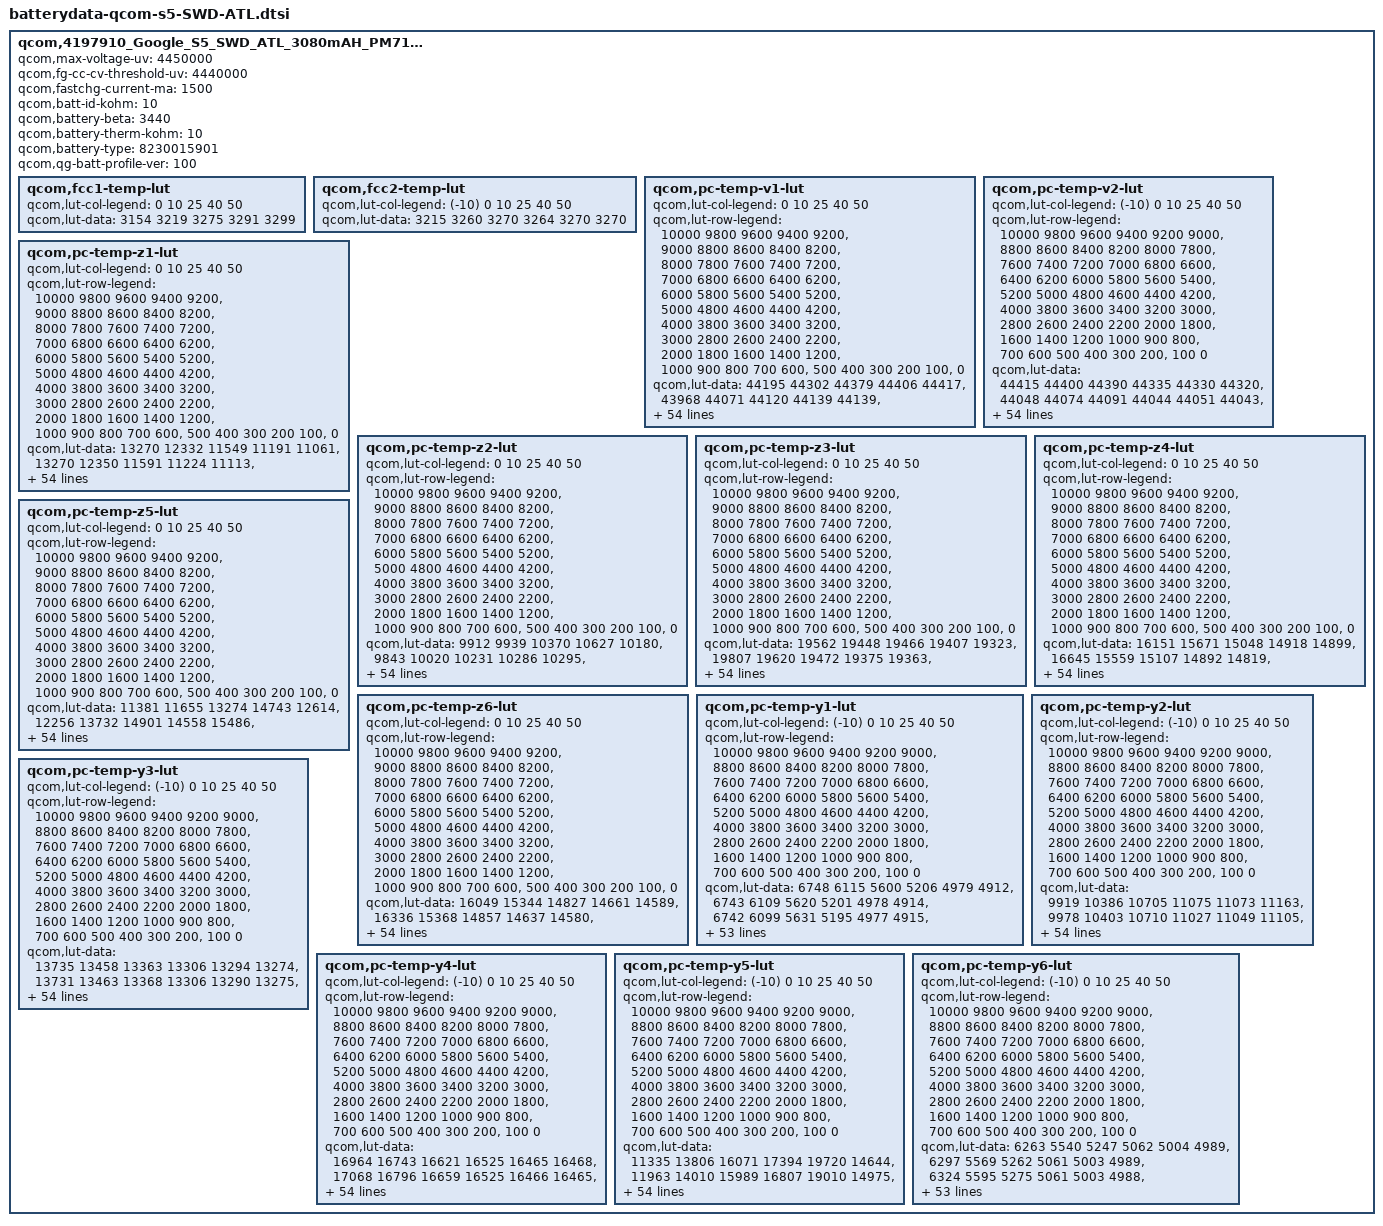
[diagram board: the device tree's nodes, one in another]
qcom,4197910_Google_S5_SWD_ATL_3080mAH_PM7150 {
	/* 4197910_Google_S5_SWD_ATL_3080mAH_PM7150_averaged_MasterSlave_Oct30th2019 */
	qcom,max-voltage-uv = <4450000>;
	qcom,fg-cc-cv-threshold-uv = <4440000>;
	qcom,fastchg-current-ma = <1500>;
	qcom,batt-id-kohm = <10>;
	qcom,battery-beta = <3440>;
	qcom,battery-therm-kohm = <10>;
	qcom,battery-type = "8230015901";
	qcom,qg-batt-profile-ver = <100>;

	qcom,fcc1-temp-lut {
		qcom,lut-col-legend = <0 10 25 40 50>;
		qcom,lut-data = <3154 3219 3275 3291 3299>;
	};

	qcom,fcc2-temp-lut {
		qcom,lut-col-legend = <(-10) 0 10 25 40 50>;
		qcom,lut-data = <3215 3260 3270 3264 3270 3270>;
	};

	qcom,pc-temp-v1-lut {
		qcom,lut-col-legend = <0 10 25 40 50>;
		qcom,lut-row-legend = <10000 9800 9600 9400 9200>,
			<9000 8800 8600 8400 8200>,
			<8000 7800 7600 7400 7200>,
			<7000 6800 6600 6400 6200>,
			<6000 5800 5600 5400 5200>,
			<5000 4800 4600 4400 4200>,
			<4000 3800 3600 3400 3200>,
			<3000 2800 2600 2400 2200>,
			<2000 1800 1600 1400 1200>,
			<1000 900 800 700 600>,
			<500 400 300 200 100>,
			<0>;
		qcom,lut-data = <44195 44302 44379 44406 44417>,
			<43968 44071 44120 44139 44139>,
			<43737 43855 43900 43911 43914>,
			<43509 43632 43686 43701 43703>,
			<43275 43408 43463 43482 43495>,
			<43030 43174 43232 43259 43274>,
			<42784 42930 42992 43027 43044>,
			<42539 42684 42744 42786 42804>,
			<42294 42437 42496 42541 42560>,
			<42054 42191 42249 42294 42317>,
			<41819 41950 42004 42047 42074>,
			<41588 41712 41764 41806 41833>,
			<41363 41481 41529 41570 41594>,
			<41145 41256 41298 41337 41359>,
			<40936 41038 41073 41110 41130>,
			<40735 40828 40855 40889 40909>,
			<40535 40626 40647 40677 40696>,
			<40328 40428 40446 40473 40492>,
			<40129 40236 40258 40280 40297>,
			<39961 40052 40078 40096 40111>,
			<39811 39890 39901 39916 39928>,
			<39654 39722 39732 39744 39752>,
			<39489 39485 39537 39557 39565>,
			<39314 39185 39268 39315 39332>,
			<39109 38976 39024 39076 39095>,
			<38894 38847 38888 38916 38927>,
			<38738 38744 38787 38793 38795>,
			<38623 38653 38684 38680 38679>,
			<38536 38575 38581 38573 38572>,
			<38474 38498 38488 38474 38474>,
			<38425 38426 38405 38384 38381>,
			<38377 38359 38331 38302 38296>,
			<38332 38299 38266 38230 38219>,
			<38291 38245 38208 38165 38148>,
			<38255 38200 38157 38107 38083>,
			<38220 38160 38114 38057 38026>,
			<38185 38121 38069 38004 37964>,
			<38152 38086 38025 37944 37888>,
			<38105 38040 37974 37875 37802>,
			<38022 37957 37894 37791 37711>,
			<37914 37840 37782 37688 37612>,
			<37792 37715 37661 37573 37499>,
			<37648 37574 37527 37439 37364>,
			<37486 37410 37367 37283 37210>,
			<37329 37248 37198 37122 37054>,
			<37217 37137 37093 37029 36967>,
			<37178 37107 37067 37006 36944>,
			<37143 37087 37050 36991 36929>,
			<37112 37064 37032 36973 36912>,
			<37077 37029 36992 36932 36861>,
			<36930 36851 36793 36715 36621>,
			<36527 36432 36363 36278 36176>,
			<35957 35848 35784 35704 35600>,
			<35169 35042 34995 34923 34818>,
			<33828 33703 33772 33723 33607>,
			<30000 30000 30000 30000 30000>;
	};

	qcom,pc-temp-v2-lut {
		qcom,lut-col-legend = <(-10) 0 10 25 40 50>;
		qcom,lut-row-legend = <10000 9800 9600 9400 9200 9000>,
			<8800 8600 8400 8200 8000 7800>,
			<7600 7400 7200 7000 6800 6600>,
			<6400 6200 6000 5800 5600 5400>,
			<5200 5000 4800 4600 4400 4200>,
			<4000 3800 3600 3400 3200 3000>,
			<2800 2600 2400 2200 2000 1800>,
			<1600 1400 1200 1000 900 800>,
			<700 600 500 400 300 200>,
			<100 0>;
		qcom,lut-data = <44415 44400 44390 44335 44330 44320>,
			<44048 44074 44091 44044 44051 44043>,
			<43724 43783 43819 43776 43791 43784>,
			<43456 43536 43579 43535 43554 43549>,
			<43230 43324 43367 43318 43336 43334>,
			<43001 43100 43143 43091 43110 43110>,
			<42765 42859 42904 42852 42873 42875>,
			<42524 42613 42660 42609 42632 42636>,
			<42274 42364 42413 42364 42390 42394>,
			<42020 42113 42165 42118 42146 42151>,
			<41775 41871 41921 41876 41906 41910>,
			<41534 41636 41682 41636 41666 41671>,
			<41307 41403 41447 41402 41432 41438>,
			<41112 41166 41216 41173 41201 41209>,
			<40917 40941 40992 40950 40977 40986>,
			<40675 40748 40780 40733 40761 40769>,
			<40386 40567 40575 40523 40551 40558>,
			<40108 40334 40365 40323 40348 40356>,
			<39851 40028 40154 40134 40154 40162>,
			<39601 39747 39930 39941 39964 39974>,
			<39353 39523 39677 39742 39786 39797>,
			<39113 39320 39429 39535 39600 39612>,
			<38904 39126 39215 39304 39364 39378>,
			<38719 38942 39021 39061 39103 39118>,
			<38558 38775 38851 38873 38910 38925>,
			<38413 38625 38701 38727 38766 38779>,
			<38291 38479 38566 38600 38640 38652>,
			<38207 38321 38443 38483 38525 38538>,
			<38142 38177 38330 38378 38422 38435>,
			<38083 38077 38228 38281 38326 38337>,
			<38029 38002 38134 38194 38238 38246>,
			<37976 37944 38041 38112 38157 38163>,
			<37921 37901 37945 38037 38083 38088>,
			<37864 37860 37867 37967 38011 38015>,
			<37806 37813 37818 37903 37942 37943>,
			<37745 37764 37776 37841 37871 37865>,
			<37679 37712 37734 37771 37781 37761>,
			<37610 37656 37692 37695 37673 37633>,
			<37535 37591 37639 37615 37570 37518>,
			<37452 37511 37568 37528 37473 37421>,
			<37361 37416 37479 37442 37385 37331>,
			<37266 37304 37364 37355 37300 37243>,
			<37168 37183 37221 37225 37173 37110>,
			<37079 37036 37074 37094 37048 36982>,
			<36984 36872 36886 36926 36890 36835>,
			<36891 36779 36807 36877 36852 36803>,
			<36851 36747 36778 36865 36844 36792>,
			<36808 36718 36747 36851 36831 36779>,
			<36767 36682 36708 36829 36806 36752>,
			<36716 36621 36656 36768 36746 36674>,
			<36633 36457 36434 36550 36493 36377>,
			<36457 36042 35968 36092 36022 35889>,
			<36089 35361 35321 35480 35400 35254>,
			<35473 34361 34424 34655 34552 34376>,
			<34478 32835 33014 33398 33277 33030>,
			<33109 29469 28345 27904 28744 28474>;
	};

	qcom,pc-temp-z1-lut {
		qcom,lut-col-legend = <0 10 25 40 50>;
		qcom,lut-row-legend = <10000 9800 9600 9400 9200>,
			<9000 8800 8600 8400 8200>,
			<8000 7800 7600 7400 7200>,
			<7000 6800 6600 6400 6200>,
			<6000 5800 5600 5400 5200>,
			<5000 4800 4600 4400 4200>,
			<4000 3800 3600 3400 3200>,
			<3000 2800 2600 2400 2200>,
			<2000 1800 1600 1400 1200>,
			<1000 900 800 700 600>,
			<500 400 300 200 100>,
			<0>;
		qcom,lut-data = <13270 12332 11549 11191 11061>,
			<13270 12350 11591 11224 11113>,
			<13253 12328 11582 11219 11112>,
			<13229 12323 11562 11211 11108>,
			<13212 12292 11547 11201 11103>,
			<13190 12270 11536 11197 11101>,
			<13175 12255 11526 11194 11100>,
			<13174 12244 11517 11192 11099>,
			<13173 12232 11511 11190 11098>,
			<13169 12223 11508 11189 11097>,
			<13151 12220 11506 11187 11096>,
			<13133 12219 11503 11186 11096>,
			<13111 12217 11501 11185 11096>,
			<13087 12203 11500 11185 11096>,
			<13072 12190 11500 11185 11097>,
			<13058 12192 11501 11186 11099>,
			<13053 12198 11502 11187 11100>,
			<13063 12199 11504 11189 11101>,
			<13076 12196 11506 11190 11103>,
			<13087 12197 11510 11193 11105>,
			<13105 12205 11513 11195 11107>,
			<13115 12215 11517 11197 11109>,
			<13126 12218 11521 11199 11111>,
			<13135 12217 11527 11203 11113>,
			<13127 12221 11535 11206 11117>,
			<13108 12238 11542 11211 11121>,
			<13105 12253 11549 11216 11124>,
			<13117 12257 11555 11221 11128>,
			<13131 12260 11561 11225 11131>,
			<13147 12261 11567 11229 11134>,
			<13162 12267 11575 11233 11137>,
			<13164 12278 11582 11236 11140>,
			<13163 12327 11588 11241 11143>,
			<13166 12379 11594 11245 11147>,
			<13176 12365 11600 11250 11150>,
			<13187 12313 11605 11254 11153>,
			<13197 12297 11611 11259 11156>,
			<13208 12315 11619 11263 11160>,
			<13218 12331 11627 11268 11164>,
			<13236 12335 11634 11271 11166>,
			<13259 12340 11641 11274 11168>,
			<13291 12350 11647 11277 11170>,
			<13323 12366 11652 11279 11172>,
			<13302 12373 11658 11282 11174>,
			<13280 12381 11665 11285 11175>,
			<13320 12389 11676 11289 11177>,
			<13329 12387 11674 11289 11177>,
			<13332 12366 11674 11290 11177>,
			<13325 12362 11680 11291 11178>,
			<13320 12379 11686 11294 11181>,
			<13388 12410 11699 11299 11185>,
			<13355 12420 11713 11307 11191>,
			<13403 12445 11722 11319 11199>,
			<13399 12486 11751 11335 11213>,
			<13399 12486 11751 11335 11213>,
			<13399 12486 11751 11335 11213>;
	};

	qcom,pc-temp-z2-lut {
		qcom,lut-col-legend = <0 10 25 40 50>;
		qcom,lut-row-legend = <10000 9800 9600 9400 9200>,
			<9000 8800 8600 8400 8200>,
			<8000 7800 7600 7400 7200>,
			<7000 6800 6600 6400 6200>,
			<6000 5800 5600 5400 5200>,
			<5000 4800 4600 4400 4200>,
			<4000 3800 3600 3400 3200>,
			<3000 2800 2600 2400 2200>,
			<2000 1800 1600 1400 1200>,
			<1000 900 800 700 600>,
			<500 400 300 200 100>,
			<0>;
		qcom,lut-data = <9912 9939 10370 10627 10180>,
			<9843 10020 10231 10286 10295>,
			<9833 10025 10237 10354 10266>,
			<9846 10013 10208 10362 10319>,
			<9850 9974 10161 10322 10365>,
			<9846 9942 10126 10273 10320>,
			<9841 9912 10123 10261 10299>,
			<9836 9896 10124 10268 10295>,
			<9830 9895 10127 10276 10289>,
			<9823 9894 10140 10290 10249>,
			<9816 9901 10155 10303 10193>,
			<9810 9927 10167 10292 10189>,
			<9810 9949 10178 10264 10200>,
			<9814 9963 10188 10251 10210>,
			<9818 9975 10198 10248 10219>,
			<9824 9986 10206 10248 10230>,
			<9831 9996 10212 10247 10249>,
			<9837 10010 10217 10243 10273>,
			<9844 10028 10222 10247 10290>,
			<9857 10042 10226 10264 10303>,
			<9875 10049 10229 10273 10317>,
			<9889 10055 10230 10286 10332>,
			<9898 10066 10230 10299 10352>,
			<9906 10083 10211 10306 10406>,
			<9916 10087 10193 10317 10469>,
			<9927 10066 10219 10359 10465>,
			<9936 10049 10272 10441 10416>,
			<9943 10052 10284 10455 10353>,
			<9948 10060 10275 10364 10250>,
			<9951 10065 10263 10301 10187>,
			<9953 10068 10229 10299 10192>,
			<9957 10070 10198 10300 10203>,
			<9962 10073 10205 10311 10218>,
			<9967 10075 10229 10344 10248>,
			<9971 10079 10249 10373 10284>,
			<9975 10085 10266 10401 10339>,
			<9979 10091 10278 10430 10397>,
			<9984 10095 10285 10469 10470>,
			<9989 10101 10292 10504 10539>,
			<9995 10112 10315 10522 10565>,
			<10001 10124 10353 10539 10592>,
			<10006 10123 10363 10544 10585>,
			<10012 10117 10353 10541 10511>,
			<10027 10123 10355 10543 10475>,
			<10106 10168 10375 10548 10469>,
			<10163 10289 10426 10480 10495>,
			<10116 10302 10402 10478 10509>,
			<10026 10444 10372 10468 10505>,
			<10024 10541 10364 10459 10534>,
			<9985 10633 10399 10523 10554>,
			<9997 10564 10502 10454 10407>,
			<9892 10479 10578 10355 10273>,
			<9698 10364 10568 10308 10223>,
			<9582 10197 10506 10261 10202>,
			<9582 10197 10506 10261 10202>,
			<9582 10197 10506 10261 10202>;
	};

	qcom,pc-temp-z3-lut {
		qcom,lut-col-legend = <0 10 25 40 50>;
		qcom,lut-row-legend = <10000 9800 9600 9400 9200>,
			<9000 8800 8600 8400 8200>,
			<8000 7800 7600 7400 7200>,
			<7000 6800 6600 6400 6200>,
			<6000 5800 5600 5400 5200>,
			<5000 4800 4600 4400 4200>,
			<4000 3800 3600 3400 3200>,
			<3000 2800 2600 2400 2200>,
			<2000 1800 1600 1400 1200>,
			<1000 900 800 700 600>,
			<500 400 300 200 100>,
			<0>;
		qcom,lut-data = <19562 19448 19466 19407 19323>,
			<19807 19620 19472 19375 19363>,
			<19926 19687 19478 19397 19358>,
			<19993 19745 19539 19420 19381>,
			<20016 19762 19553 19456 19408>,
			<20023 19765 19556 19458 19408>,
			<20025 19762 19554 19456 19408>,
			<20017 19759 19543 19440 19405>,
			<20006 19752 19532 19427 19400>,
			<20001 19740 19520 19423 19389>,
			<20000 19725 19507 19420 19377>,
			<19997 19703 19492 19411 19373>,
			<19989 19688 19479 19396 19371>,
			<19977 19675 19475 19389 19368>,
			<19963 19666 19474 19387 19366>,
			<19945 19663 19472 19385 19362>,
			<19929 19661 19468 19383 19357>,
			<19914 19656 19464 19380 19350>,
			<19899 19644 19461 19377 19347>,
			<19884 19637 19457 19374 19345>,
			<19869 19635 19457 19373 19344>,
			<19865 19634 19460 19373 19347>,
			<19876 19644 19463 19372 19348>,
			<19892 19675 19466 19365 19344>,
			<19906 19685 19468 19355 19339>,
			<19919 19668 19459 19366 19351>,
			<19921 19650 19440 19399 19394>,
			<19916 19642 19444 19414 19407>,
			<19908 19636 19483 19420 19396>,
			<19897 19638 19504 19422 19383>,
			<19884 19648 19502 19418 19376>,
			<19877 19655 19499 19411 19371>,
			<19872 19656 19494 19405 19366>,
			<19869 19657 19488 19397 19362>,
			<19866 19655 19482 19390 19357>,
			<19863 19650 19478 19383 19350>,
			<19859 19644 19474 19380 19346>,
			<19853 19639 19472 19381 19349>,
			<19845 19633 19470 19383 19354>,
			<19833 19626 19466 19383 19356>,
			<19819 19618 19460 19379 19357>,
			<19808 19611 19454 19377 19357>,
			<19796 19606 19446 19374 19351>,
			<19766 19597 19441 19374 19350>,
			<19657 19570 19437 19375 19353>,
			<19377 19515 19416 19358 19336>,
			<19344 19498 19412 19356 19335>,
			<19336 19394 19403 19349 19333>,
			<19329 19346 19396 19348 19326>,
			<19322 19335 19393 19342 19329>,
			<19325 19344 19371 19356 19351>,
			<19335 19338 19360 19369 19358>,
			<19346 19331 19351 19372 19360>,
			<19371 19349 19354 19372 19348>,
			<19371 19349 19354 19372 19348>,
			<19371 19349 19354 19372 19348>;
	};

	qcom,pc-temp-z4-lut {
		qcom,lut-col-legend = <0 10 25 40 50>;
		qcom,lut-row-legend = <10000 9800 9600 9400 9200>,
			<9000 8800 8600 8400 8200>,
			<8000 7800 7600 7400 7200>,
			<7000 6800 6600 6400 6200>,
			<6000 5800 5600 5400 5200>,
			<5000 4800 4600 4400 4200>,
			<4000 3800 3600 3400 3200>,
			<3000 2800 2600 2400 2200>,
			<2000 1800 1600 1400 1200>,
			<1000 900 800 700 600>,
			<500 400 300 200 100>,
			<0>;
		qcom,lut-data = <16151 15671 15048 14918 14899>,
			<16645 15559 15107 14892 14819>,
			<16704 15562 14974 14822 14776>,
			<16301 15603 15110 14842 14772>,
			<15993 15369 15066 14886 14833>,
			<15770 15215 14967 14836 14793>,
			<15591 15119 14904 14807 14768>,
			<15458 15043 14856 14793 14757>,
			<15351 14978 14830 14781 14751>,
			<15256 14928 14819 14768 14749>,
			<15171 14899 14811 14758 14748>,
			<15100 14877 14805 14754 14743>,
			<15038 14863 14800 14753 14733>,
			<14987 14854 14792 14749 14723>,
			<14955 14845 14778 14738 14714>,
			<14929 14833 14767 14726 14706>,
			<14920 14818 14759 14717 14701>,
			<14926 14814 14753 14709 14696>,
			<14934 14815 14748 14703 14690>,
			<14927 14814 14743 14699 14684>,
			<14902 14801 14743 14698 14682>,
			<14881 14785 14746 14704 14687>,
			<14863 14820 14754 14716 14696>,
			<14852 14927 14850 14797 14760>,
			<14886 14971 14942 14892 14843>,
			<14961 14976 14942 14883 14833>,
			<14996 14978 14934 14830 14769>,
			<15011 14967 14913 14791 14739>,
			<15017 14940 14851 14763 14733>,
			<15008 14914 14807 14744 14728>,
			<14988 14886 14790 14732 14719>,
			<14971 14865 14781 14723 14710>,
			<14954 14852 14778 14719 14702>,
			<14938 14842 14776 14717 14695>,
			<14922 14837 14776 14716 14694>,
			<14906 14833 14776 14719 14698>,
			<14889 14828 14777 14724 14705>,
			<14870 14820 14779 14734 14718>,
			<14855 14814 14782 14745 14732>,
			<14845 14812 14787 14749 14732>,
			<14836 14810 14791 14751 14727>,
			<14821 14803 14790 14750 14721>,
			<14805 14782 14772 14737 14716>,
			<14797 14765 14759 14731 14715>,
			<14822 14743 14746 14728 14716>,
			<15014 14710 14704 14699 14693>,
			<15047 14717 14693 14690 14681>,
			<15050 14819 14684 14673 14662>,
			<15050 14865 14675 14655 14648>,
			<15048 14867 14673 14659 14645>,
			<15035 14867 14716 14665 14646>,
			<15050 14885 14733 14661 14646>,
			<15065 14904 14745 14658 14644>,
			<15076 14902 14744 14657 14653>,
			<15076 14902 14744 14657 14653>,
			<15076 14902 14744 14657 14653>;
	};

	qcom,pc-temp-z5-lut {
		qcom,lut-col-legend = <0 10 25 40 50>;
		qcom,lut-row-legend = <10000 9800 9600 9400 9200>,
			<9000 8800 8600 8400 8200>,
			<8000 7800 7600 7400 7200>,
			<7000 6800 6600 6400 6200>,
			<6000 5800 5600 5400 5200>,
			<5000 4800 4600 4400 4200>,
			<4000 3800 3600 3400 3200>,
			<3000 2800 2600 2400 2200>,
			<2000 1800 1600 1400 1200>,
			<1000 900 800 700 600>,
			<500 400 300 200 100>,
			<0>;
		qcom,lut-data = <11381 11655 13274 14743 12614>,
			<12256 13732 14901 14558 15486>,
			<12500 14174 16246 17046 16252>,
			<12932 14082 15204 17318 18486>,
			<13297 14652 15395 16952 17019>,
			<13593 15106 15935 17466 17619>,
			<13881 15487 16530 17553 18024>,
			<14164 15889 17253 17292 18248>,
			<14455 16432 17477 17150 18346>,
			<14829 16963 17335 17374 17688>,
			<15337 17322 17117 17640 16735>,
			<15925 17734 16788 17340 16691>,
			<16731 17963 16452 16507 16946>,
			<17533 18091 16542 16303 17239>,
			<17987 18286 17137 16668 17642>,
			<18473 18977 17688 17113 17867>,
			<18672 20052 18080 17563 17688>,
			<18623 20211 18479 18013 17442>,
			<18585 19714 18952 18414 17551>,
			<18651 19436 19510 18896 18097>,
			<18826 20661 20374 19208 18717>,
			<19351 23243 21821 19443 19562>,
			<23269 27860 22418 19525 20029>,
			<28359 35329 22177 17574 17684>,
			<32772 37320 21683 15073 14289>,
			<36894 30679 19673 15013 14724>,
			<37552 24041 16348 15580 17341>,
			<34973 21962 16047 16365 18236>,
			<31965 20715 18290 17745 18002>,
			<29529 20786 20554 19228 17813>,
			<27448 22219 22256 20549 18229>,
			<26817 23931 23857 21775 19124>,
			<26573 25948 25435 22871 20237>,
			<26493 27865 26912 23853 21654>,
			<26814 28972 27844 24117 22044>,
			<27399 29791 28545 24108 21749>,
			<27950 30120 28810 24074 21524>,
			<28549 30051 28500 24042 21621>,
			<28963 29858 27856 23984 21763>,
			<29381 29348 26703 23284 21664>,
			<29688 28580 24871 21392 21260>,
			<29433 28255 23630 20526 20714>,
			<28440 28074 22636 20265 19795>,
			<25766 27423 22340 20096 19208>,
			<20243 26413 22374 19830 18792>,
			<12271 24351 24056 19616 17712>,
			<11521 20705 23134 19932 18273>,
			<11408 13569 21902 20493 20077>,
			<11336 12033 20788 23385 22470>,
			<11291 11907 20566 21342 23259>,
			<11394 12101 15812 19871 24036>,
			<11366 11899 14164 20740 24332>,
			<11313 11697 13448 20887 24181>,
			<11381 11828 13358 20277 18813>,
			<11381 11828 13358 20277 18813>,
			<11381 11828 13358 20277 18813>;
	};

	qcom,pc-temp-z6-lut {
		qcom,lut-col-legend = <0 10 25 40 50>;
		qcom,lut-row-legend = <10000 9800 9600 9400 9200>,
			<9000 8800 8600 8400 8200>,
			<8000 7800 7600 7400 7200>,
			<7000 6800 6600 6400 6200>,
			<6000 5800 5600 5400 5200>,
			<5000 4800 4600 4400 4200>,
			<4000 3800 3600 3400 3200>,
			<3000 2800 2600 2400 2200>,
			<2000 1800 1600 1400 1200>,
			<1000 900 800 700 600>,
			<500 400 300 200 100>,
			<0>;
		qcom,lut-data = <16049 15344 14827 14661 14589>,
			<16336 15368 14857 14637 14580>,
			<16374 15383 14797 14617 14559>,
			<16208 15413 14884 14638 14569>,
			<16067 15309 14868 14675 14611>,
			<15949 15233 14825 14656 14594>,
			<15848 15180 14794 14639 14583>,
			<15768 15135 14766 14624 14576>,
			<15701 15095 14746 14613 14571>,
			<15643 15061 14734 14605 14564>,
			<15593 15035 14724 14598 14557>,
			<15549 15014 14713 14591 14551>,
			<15510 14999 14703 14583 14546>,
			<15477 14987 14696 14576 14540>,
			<15451 14978 14689 14570 14535>,
			<15428 14969 14684 14564 14530>,
			<15415 14961 14679 14559 14524>,
			<15410 14955 14674 14554 14519>,
			<15405 14950 14670 14550 14514>,
			<15394 14945 14667 14547 14511>,
			<15377 14939 14667 14546 14510>,
			<15372 14935 14670 14549 14513>,
			<15375 14957 14677 14554 14519>,
			<15381 15021 14722 14587 14546>,
			<15404 15045 14763 14624 14580>,
			<15446 15041 14760 14626 14583>,
			<15464 15035 14749 14621 14579>,
			<15471 15027 14742 14615 14574>,
			<15474 15016 14737 14607 14565>,
			<15467 15009 14732 14600 14557>,
			<15454 15004 14726 14592 14550>,
			<15445 15000 14720 14586 14543>,
			<15439 14997 14717 14580 14537>,
			<15434 14995 14714 14575 14531>,
			<15429 14993 14712 14572 14529>,
			<15425 14991 14711 14571 14528>,
			<15420 14989 14711 14570 14527>,
			<15416 14986 14712 14575 14534>,
			<15413 14984 14714 14582 14543>,
			<15412 14984 14715 14583 14544>,
			<15411 14984 14715 14583 14543>,
			<15410 14982 14714 14582 14541>,
			<15406 14977 14704 14576 14536>,
			<15399 14970 14698 14574 14536>,
			<15370 14954 14692 14574 14538>,
			<15322 14920 14667 14552 14520>,
			<15318 14914 14660 14547 14514>,
			<15316 14906 14652 14536 14504>,
			<15314 14905 14645 14528 14494>,
			<15317 14904 14645 14527 14495>,
			<15325 14914 14655 14539 14508>,
			<15347 14927 14661 14545 14513>,
			<15378 14944 14666 14548 14516>,
			<15427 14973 14673 14551 14517>,
			<15427 14973 14673 14551 14517>,
			<15427 14973 14673 14551 14517>;
	};

	qcom,pc-temp-y1-lut {
		qcom,lut-col-legend = <(-10) 0 10 25 40 50>;
		qcom,lut-row-legend = <10000 9800 9600 9400 9200 9000>,
			<8800 8600 8400 8200 8000 7800>,
			<7600 7400 7200 7000 6800 6600>,
			<6400 6200 6000 5800 5600 5400>,
			<5200 5000 4800 4600 4400 4200>,
			<4000 3800 3600 3400 3200 3000>,
			<2800 2600 2400 2200 2000 1800>,
			<1600 1400 1200 1000 900 800>,
			<700 600 500 400 300 200>,
			<100 0>;
		qcom,lut-data = <6748 6115 5600 5206 4979 4912>,
			<6743 6109 5620 5201 4978 4914>,
			<6742 6099 5631 5195 4977 4915>,
			<6742 6089 5635 5189 4976 4915>,
			<6744 6079 5637 5183 4975 4915>,
			<6745 6073 5636 5180 4974 4915>,
			<6755 6067 5629 5176 4973 4914>,
			<6767 6063 5622 5173 4972 4913>,
			<6775 6069 5617 5170 4971 4912>,
			<6787 6079 5610 5167 4970 4911>,
			<6789 6082 5607 5165 4968 4911>,
			<6780 6087 5605 5163 4966 4912>,
			<6774 6087 5604 5162 4965 4912>,
			<6777 6074 5600 5160 4966 4911>,
			<6780 6063 5597 5159 4967 4910>,
			<6783 6067 5599 5158 4967 4910>,
			<6792 6078 5603 5158 4967 4910>,
			<6796 6087 5602 5158 4968 4911>,
			<6799 6095 5597 5161 4968 4912>,
			<6800 6102 5594 5164 4969 4913>,
			<6798 6106 5599 5166 4969 4914>,
			<6795 6110 5605 5169 4969 4915>,
			<6790 6114 5607 5172 4970 4917>,
			<6773 6118 5609 5177 4972 4918>,
			<6764 6118 5610 5181 4974 4919>,
			<6768 6105 5612 5184 4976 4920>,
			<6775 6097 5614 5188 4979 4921>,
			<6778 6105 5618 5192 4981 4922>,
			<6779 6117 5622 5197 4983 4924>,
			<6785 6124 5624 5201 4986 4926>,
			<6810 6127 5628 5205 4989 4927>,
			<6829 6126 5630 5210 4991 4929>,
			<6821 6114 5632 5217 4993 4931>,
			<6803 6104 5634 5224 4996 4933>,
			<6790 6108 5636 5229 4999 4936>,
			<6775 6114 5639 5234 5003 4938>,
			<6768 6114 5642 5236 5005 4939>,
			<6772 6115 5649 5239 5007 4940>,
			<6778 6132 5656 5242 5008 4941>,
			<6773 6347 5664 5245 5011 4944>,
			<6762 6411 5679 5250 5012 4945>,
			<6786 6140 5699 5257 5014 4946>,
			<6806 6161 5694 5267 5016 4948>,
			<6829 6171 5700 5265 5019 4950>,
			<6889 6448 5711 5270 5022 4952>,
			<6879 6183 5716 5278 5025 4953>,
			<6860 6195 5735 5290 5025 4954>,
			<6893 6212 5713 5286 5026 4954>,
			<6937 6188 5719 5286 5027 4955>,
			<7001 6207 5731 5291 5028 4954>,
			<7037 6230 5740 5306 5028 4958>,
			<7098 6334 5752 5315 5033 4961>,
			<7202 6469 5779 5329 5041 4965>,
			<7379 6554 5901 5357 5049 4974>,
			<7379 6554 5901 5357 5049 4974>,
			<7379 6554 5901 5357 5049 4974>;
	};

	qcom,pc-temp-y2-lut {
		qcom,lut-col-legend = <(-10) 0 10 25 40 50>;
		qcom,lut-row-legend = <10000 9800 9600 9400 9200 9000>,
			<8800 8600 8400 8200 8000 7800>,
			<7600 7400 7200 7000 6800 6600>,
			<6400 6200 6000 5800 5600 5400>,
			<5200 5000 4800 4600 4400 4200>,
			<4000 3800 3600 3400 3200 3000>,
			<2800 2600 2400 2200 2000 1800>,
			<1600 1400 1200 1000 900 800>,
			<700 600 500 400 300 200>,
			<100 0>;
		qcom,lut-data = <9919 10386 10705 11075 11073 11163>,
			<9978 10403 10710 11027 11049 11105>,
			<10043 10432 10707 10979 11023 11044>,
			<10104 10461 10698 10933 10996 10986>,
			<10154 10483 10686 10895 10967 10939>,
			<10184 10489 10671 10868 10937 10910>,
			<10202 10486 10650 10849 10897 10891>,
			<10214 10484 10629 10834 10872 10875>,
			<10219 10485 10613 10820 10871 10855>,
			<10223 10488 10601 10810 10874 10837>,
			<10255 10485 10601 10810 10880 10829>,
			<10420 10472 10609 10816 10897 10825>,
			<10525 10469 10619 10822 10907 10828>,
			<10464 10546 10631 10828 10911 10862>,
			<10380 10621 10648 10835 10912 10900>,
			<10396 10613 10686 10852 10920 10915>,
			<10483 10592 10743 10882 10936 10927>,
			<10518 10594 10785 10920 10955 10945>,
			<10511 10636 10822 10973 10987 10971>,
			<10495 10669 10836 11019 11036 11005>,
			<10260 10684 10826 11058 11156 11100>,
			<9804 10692 10817 11083 11256 11184>,
			<9687 10695 10818 11061 11194 11156>,
			<9679 10697 10822 11006 11056 11084>,
			<9674 10696 10826 10995 11036 11071>,
			<9669 10686 10832 11017 11101 11102>,
			<9667 10672 10838 11035 11151 11141>,
			<9665 10645 10845 11039 11164 11181>,
			<9664 10618 10849 11043 11174 11225>,
			<9663 10617 10835 11059 11205 11272>,
			<9662 10625 10800 11092 11253 11323>,
			<9661 10624 10793 11102 11283 11351>,
			<9660 10573 10804 11096 11301 11368>,
			<9659 10479 10810 11092 11316 11378>,
			<9658 10206 10794 11091 11339 11407>,
			<9658 9842 10763 11092 11359 11444>,
			<9657 9735 10733 11086 11322 11423>,
			<9657 9695 10698 11067 11227 11341>,
			<9656 9677 10655 11043 11184 11290>,
			<9656 9671 10596 11006 11173 11260>,
			<9656 9666 10531 10988 11179 11255>,
			<9656 9662 10457 10998 11213 11235>,
			<9656 9660 10404 10973 11203 11207>,
			<9655 9660 10373 10977 11204 11206>,
			<9655 9658 10007 10882 11154 11229>,
			<9654 9655 9883 10870 11063 11071>,
			<9654 9655 9822 10862 11070 11019>,
			<9653 9654 9742 10864 11034 10984>,
			<9652 9653 9698 10862 11025 10929>,
			<9651 9652 9672 10829 11024 10934>,
			<9648 9651 9663 10789 10990 10945>,
			<9647 9648 9656 10730 10944 10867>,
			<9647 9647 9652 10669 10886 10810>,
			<9646 9647 9649 10602 10821 10712>,
			<9646 9647 9649 10602 10821 10712>,
			<9646 9647 9649 10602 10821 10712>;
	};

	qcom,pc-temp-y3-lut {
		qcom,lut-col-legend = <(-10) 0 10 25 40 50>;
		qcom,lut-row-legend = <10000 9800 9600 9400 9200 9000>,
			<8800 8600 8400 8200 8000 7800>,
			<7600 7400 7200 7000 6800 6600>,
			<6400 6200 6000 5800 5600 5400>,
			<5200 5000 4800 4600 4400 4200>,
			<4000 3800 3600 3400 3200 3000>,
			<2800 2600 2400 2200 2000 1800>,
			<1600 1400 1200 1000 900 800>,
			<700 600 500 400 300 200>,
			<100 0>;
		qcom,lut-data = <13735 13458 13363 13306 13294 13274>,
			<13731 13463 13368 13306 13290 13275>,
			<13726 13470 13372 13306 13287 13276>,
			<13722 13479 13377 13307 13285 13278>,
			<13718 13485 13381 13307 13284 13279>,
			<13717 13487 13383 13308 13284 13280>,
			<13718 13488 13385 13309 13285 13282>,
			<13719 13488 13387 13310 13287 13283>,
			<13711 13487 13388 13311 13290 13284>,
			<13693 13485 13389 13312 13295 13285>,
			<13685 13481 13390 13313 13297 13285>,
			<13689 13473 13391 13314 13298 13286>,
			<13688 13468 13391 13315 13299 13287>,
			<13636 13467 13388 13317 13299 13290>,
			<13570 13465 13384 13318 13299 13294>,
			<13566 13458 13381 13317 13300 13294>,
			<13582 13446 13377 13316 13301 13294>,
			<13587 13439 13377 13316 13300 13294>,
			<13555 13436 13379 13318 13298 13294>,
			<13525 13432 13380 13319 13298 13293>,
			<13527 13426 13372 13320 13300 13295>,
			<13533 13420 13362 13321 13302 13296>,
			<13537 13414 13357 13318 13297 13292>,
			<13541 13408 13353 13309 13288 13283>,
			<13544 13403 13350 13305 13285 13279>,
			<13535 13398 13348 13303 13285 13278>,
			<13524 13393 13346 13302 13285 13278>,
			<13529 13388 13345 13301 13284 13279>,
			<13556 13383 13343 13301 13283 13280>,
			<13590 13373 13342 13301 13283 13280>,
			<13639 13359 13342 13302 13284 13279>,
			<13696 13355 13340 13302 13284 13278>,
			<13751 13363 13338 13302 13283 13278>,
			<13810 13375 13337 13302 13283 13279>,
			<13873 13385 13338 13303 13284 13279>,
			<13940 13398 13341 13303 13285 13279>,
			<14008 13420 13344 13303 13284 13279>,
			<14080 13463 13349 13303 13282 13277>,
			<14147 13505 13354 13302 13281 13277>,
			<14202 13543 13358 13299 13281 13277>,
			<14248 13589 13363 13298 13281 13278>,
			<14289 13650 13367 13301 13282 13278>,
			<14328 13711 13366 13301 13281 13275>,
			<14294 13688 13363 13297 13282 13275>,
			<14382 13824 13356 13296 13279 13275>,
			<14535 14044 13380 13302 13280 13278>,
			<14654 14172 13397 13306 13285 13280>,
			<14790 14315 13429 13311 13289 13284>,
			<15029 14480 13480 13316 13291 13286>,
			<15493 14694 13537 13317 13296 13288>,
			<17102 15173 13664 13319 13292 13283>,
			<21290 17306 13936 13321 13292 13284>,
			<33295 25852 14630 13331 13294 13288>,
			<65535 64161 17000 13343 13298 13290>,
			<65535 64161 17000 13343 13298 13290>,
			<65535 64161 17000 13343 13298 13290>;
	};

	qcom,pc-temp-y4-lut {
		qcom,lut-col-legend = <(-10) 0 10 25 40 50>;
		qcom,lut-row-legend = <10000 9800 9600 9400 9200 9000>,
			<8800 8600 8400 8200 8000 7800>,
			<7600 7400 7200 7000 6800 6600>,
			<6400 6200 6000 5800 5600 5400>,
			<5200 5000 4800 4600 4400 4200>,
			<4000 3800 3600 3400 3200 3000>,
			<2800 2600 2400 2200 2000 1800>,
			<1600 1400 1200 1000 900 800>,
			<700 600 500 400 300 200>,
			<100 0>;
		qcom,lut-data = <16964 16743 16621 16525 16465 16468>,
			<17068 16796 16659 16525 16466 16465>,
			<17227 16892 16704 16526 16468 16461>,
			<17391 16996 16747 16526 16470 16458>,
			<17514 17074 16777 16526 16471 16456>,
			<17549 17094 16783 16527 16472 16454>,
			<17535 17090 16776 16526 16472 16453>,
			<17516 17083 16766 16526 16472 16453>,
			<17505 17078 16760 16528 16470 16454>,
			<17496 17073 16755 16532 16465 16456>,
			<17475 17078 16756 16536 16466 16460>,
			<17421 17105 16763 16543 16470 16465>,
			<17390 17125 16773 16551 16477 16467>,
			<17498 17133 16791 16560 16485 16468>,
			<17647 17142 16816 16573 16494 16468>,
			<17606 17180 16859 16591 16503 16472>,
			<17389 17241 16908 16616 16514 16483>,
			<17234 17227 16912 16645 16528 16494>,
			<17155 17066 16892 16681 16550 16508>,
			<17099 16944 16863 16697 16574 16525>,
			<17066 16904 16803 16691 16604 16553>,
			<17041 16874 16735 16679 16625 16574>,
			<16999 16837 16691 16635 16591 16549>,
			<16925 16800 16655 16553 16513 16491>,
			<16882 16769 16635 16523 16485 16471>,
			<16877 16745 16622 16515 16476 16465>,
			<16874 16715 16613 16512 16473 16463>,
			<16876 16654 16607 16515 16477 16464>,
			<16882 16596 16603 16521 16484 16468>,
			<16884 16597 16599 16527 16492 16474>,
			<16878 16622 16594 16534 16502 16485>,
			<16873 16641 16584 16542 16514 16497>,
			<16878 16651 16554 16551 16529 16509>,
			<16890 16664 16536 16558 16539 16519>,
			<16898 16701 16545 16560 16543 16525>,
			<16904 16752 16561 16562 16546 16529>,
			<16907 16783 16582 16557 16537 16520>,
			<16908 16805 16611 16535 16508 16491>,
			<16907 16813 16636 16516 16486 16475>,
			<16903 16815 16661 16502 16472 16467>,
			<16895 16814 16667 16502 16471 16467>,
			<16881 16803 16667 16512 16477 16470>,
			<16871 16779 16635 16504 16467 16460>,
			<16834 16735 16607 16501 16466 16460>,
			<16830 16727 16637 16492 16450 16440>,
			<16850 16734 16657 16504 16462 16450>,
			<16852 16741 16675 16515 16469 16458>,
			<16867 16755 16703 16530 16477 16468>,
			<16876 16784 16745 16549 16492 16491>,
			<16912 16837 16846 16572 16508 16501>,
			<17121 16859 16808 16550 16471 16459>,
			<17750 17064 16804 16549 16463 16454>,
			<20021 19330 16861 16577 16474 16466>,
			<36928 53893 17441 16635 16508 16499>,
			<36928 53893 17441 16635 16508 16499>,
			<36928 53893 17441 16635 16508 16499>;
	};

	qcom,pc-temp-y5-lut {
		qcom,lut-col-legend = <(-10) 0 10 25 40 50>;
		qcom,lut-row-legend = <10000 9800 9600 9400 9200 9000>,
			<8800 8600 8400 8200 8000 7800>,
			<7600 7400 7200 7000 6800 6600>,
			<6400 6200 6000 5800 5600 5400>,
			<5200 5000 4800 4600 4400 4200>,
			<4000 3800 3600 3400 3200 3000>,
			<2800 2600 2400 2200 2000 1800>,
			<1600 1400 1200 1000 900 800>,
			<700 600 500 400 300 200>,
			<100 0>;
		qcom,lut-data = <11335 13806 16071 17394 19720 14644>,
			<11963 14010 15989 16807 19010 14975>,
			<12571 14264 15868 16193 17602 15341>,
			<13154 14516 15743 15619 16030 15692>,
			<13711 14715 15651 15151 14826 15976>,
			<14243 14813 15621 14850 14471 16149>,
			<14855 14864 15600 14656 14427 16275>,
			<15270 14887 15553 14507 14410 16335>,
			<15285 14806 15391 14312 15348 16202>,
			<15222 14623 15112 14069 16876 15891>,
			<15365 14461 14855 13856 16992 15509>,
			<16246 14299 14593 13609 16470 14990>,
			<16810 14156 14343 13425 15876 14853>,
			<16298 14012 14059 13291 15173 15834>,
			<15591 13922 13886 13198 14591 16727>,
			<16395 14606 13926 12960 14311 16282>,
			<19417 16144 14067 12553 14112 15298>,
			<20591 16821 14754 12537 13864 14714>,
			<19502 17070 17192 12957 13218 14188>,
			<17914 17355 18468 13683 12973 13981>,
			<16346 17848 18562 16236 14121 14478>,
			<14766 18376 18631 18660 15514 15147>,
			<14121 18770 18757 18628 16056 15775>,
			<13900 19112 18891 18216 16440 16610>,
			<13608 19452 18944 17951 16699 16677>,
			<12616 19866 18979 17550 17012 16125>,
			<11578 20071 19034 17322 17134 15824>,
			<11438 19358 19162 17094 16551 16171>,
			<11413 17956 19373 16809 15819 16575>,
			<11424 16152 19821 16916 15645 16163>,
			<11665 13489 20486 17365 15594 15071>,
			<11915 12693 20543 17739 15557 14773>,
			<11983 13174 19677 17991 15435 14826>,
			<12028 13570 18781 18313 15374 14918>,
			<12113 13250 18154 19211 16178 15368>,
			<12275 12720 17683 20314 17282 16025>,
			<12431 12723 17474 20632 17502 16349>,
			<12628 13074 17341 20667 17536 16550>,
			<12812 13289 17133 20326 17640 16958>,
			<12811 13370 16677 18148 18103 17934>,
			<12689 13335 16486 16827 17838 18124>,
			<12549 13017 16368 16693 16858 17664>,
			<12219 13075 16183 16586 17062 16001>,
			<12046 12574 16151 15841 17044 15741>,
			<11876 12223 13287 15830 17622 19303>,
			<11596 12222 13373 16427 15363 16640>,
			<11736 12311 13241 16739 15989 15946>,
			<11648 12512 12958 16521 15981 16516>,
			<11914 12612 12766 16048 15563 16045>,
			<11987 12535 12532 14792 16476 15931>,
			<11403 12574 12796 16242 18184 16863>,
			<10359 11435 12939 17055 19735 18294>,
			<9390 9551 12622 18317 20621 21828>,
			<8910 8860 11094 19098 21954 21673>,
			<8910 8860 11094 19098 21954 21673>,
			<8910 8860 11094 19098 21954 21673>;
	};

	qcom,pc-temp-y6-lut {
		qcom,lut-col-legend = <(-10) 0 10 25 40 50>;
		qcom,lut-row-legend = <10000 9800 9600 9400 9200 9000>,
			<8800 8600 8400 8200 8000 7800>,
			<7600 7400 7200 7000 6800 6600>,
			<6400 6200 6000 5800 5600 5400>,
			<5200 5000 4800 4600 4400 4200>,
			<4000 3800 3600 3400 3200 3000>,
			<2800 2600 2400 2200 2000 1800>,
			<1600 1400 1200 1000 900 800>,
			<700 600 500 400 300 200>,
			<100 0>;
		qcom,lut-data = <6263 5540 5247 5062 5004 4989>,
			<6297 5569 5262 5061 5003 4989>,
			<6324 5595 5275 5061 5003 4988>,
			<6343 5616 5285 5061 5003 4988>,
			<6354 5629 5291 5061 5003 4989>,
			<6357 5632 5291 5062 5003 4989>,
			<6349 5625 5287 5062 5004 4990>,
			<6336 5616 5282 5062 5005 4991>,
			<6321 5608 5277 5063 5007 4992>,
			<6302 5600 5273 5064 5009 4993>,
			<6288 5598 5273 5066 5011 4995>,
			<6276 5598 5273 5068 5013 4996>,
			<6269 5597 5273 5071 5015 4998>,
			<6271 5595 5275 5074 5017 5001>,
			<6273 5593 5278 5079 5020 5003>,
			<6263 5599 5286 5083 5023 5006>,
			<6227 5611 5296 5089 5027 5008>,
			<6192 5605 5298 5097 5031 5011>,
			<6163 5560 5293 5109 5036 5015>,
			<6137 5525 5285 5114 5042 5020>,
			<6114 5514 5263 5113 5052 5028>,
			<6095 5506 5238 5110 5059 5035>,
			<6085 5494 5222 5096 5046 5025>,
			<6078 5483 5210 5066 5017 5001>,
			<6075 5478 5204 5055 5007 4993>,
			<6083 5476 5200 5052 5004 4990>,
			<6099 5474 5199 5051 5003 4990>,
			<6122 5466 5198 5052 5004 4991>,
			<6159 5456 5198 5054 5006 4993>,
			<6199 5459 5199 5057 5008 4995>,
			<6245 5474 5201 5060 5012 4997>,
			<6295 5494 5200 5064 5015 5000>,
			<6347 5528 5195 5067 5019 5004>,
			<6403 5569 5192 5070 5022 5007>,
			<6461 5613 5198 5073 5025 5009>,
			<6521 5662 5211 5075 5027 5011>,
			<6580 5720 5227 5074 5024 5008>,
			<6638 5789 5249 5068 5014 4999>,
			<6693 5859 5272 5063 5008 4994>,
			<6736 5930 5300 5058 5004 4993>,
			<6773 6002 5328 5058 5004 4993>,
			<6811 6074 5355 5065 5006 4994>,
			<6849 6139 5363 5064 5003 4990>,
			<6828 6119 5355 5061 5004 4990>,
			<6915 6261 5398 5060 4997 4984>,
			<7058 6459 5487 5070 5002 4990>,
			<7161 6577 5542 5078 5007 4994>,
			<7291 6708 5613 5087 5013 4999>,
			<7513 6861 5710 5097 5019 5008>,
			<7950 7071 5841 5106 5027 5012>,
			<9388 7501 5993 5104 5013 4996>,
			<12775 9295 6294 5108 5011 4996>,
			<21974 16216 6949 5131 5017 5003>,
			<56334 52398 9058 5166 5031 5015>,
			<56334 52398 9058 5166 5031 5015>,
			<56334 52398 9058 5166 5031 5015>;
	};

};
